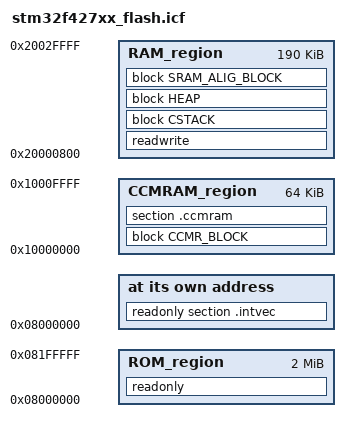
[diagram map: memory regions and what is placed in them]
/*###ICF### Section handled by ICF editor, don't touch! ****/
/*-Editor annotation file-*/
/* IcfEditorFile="$TOOLKIT_DIR$\config\ide\IcfEditor\cortex_v1_0.xml" */
/*-Specials-*/
define symbol __ICFEDIT_intvec_start__ = 0x08000000;
/*-Memory Regions-*/
define symbol __ICFEDIT_region_ROM_start__    = 0x08000000;
define symbol __ICFEDIT_region_ROM_end__      = 0x081FFFFF;
define symbol __ICFEDIT_region_RAM_start__    = 0x20000800;
define symbol __ICFEDIT_region_RAM_end__      = 0x2002FFFF;
define symbol __ICFEDIT_region_CCMRAM_start__ = 0x10000000;
define symbol __ICFEDIT_region_CCMRAM_end__   = 0x1000FFFF;
/*-Sizes-*/
define symbol __ICFEDIT_size_cstack__ = 0x1000;
define symbol __ICFEDIT_size_heap__ = 0x800;
/**** End of ICF editor section. ###ICF###*/


define memory mem with size = 4G;
define region ROM_region      = mem:[from __ICFEDIT_region_ROM_start__   to __ICFEDIT_region_ROM_end__];
define region RAM_region      = mem:[from __ICFEDIT_region_RAM_start__   to __ICFEDIT_region_RAM_end__];
define region CCMRAM_region   = mem:[from __ICFEDIT_region_CCMRAM_start__   to __ICFEDIT_region_CCMRAM_end__];

define block CSTACK    with alignment = 8, size = __ICFEDIT_size_cstack__   { };
define block HEAP      with alignment = 8, size = __ICFEDIT_size_heap__     { };

initialize by copy { readwrite };
do not initialize  { section .noinit };

place at address mem:__ICFEDIT_intvec_start__ { readonly section .intvec };

place in ROM_region   { readonly };
place in RAM_region   { readwrite,
                        block CSTACK, block HEAP };

/*自定义 SRAM存段，边界对齐方式：4字节对*/
define block SRAM_ALIG_BLOCK with alignment = 4 { section .sram_alig };
place in RAM_region { block SRAM_ALIG_BLOCK};

/*自定义 SDRAM内存段，边界对齐方式：缺省*/
/*place in SDRAM_region { section .sdram}; */

/*自定义 CCMR内存段，边界对齐方式：4字节对*/
define block CCMR_BLOCK with alignment = 4 { section .ccmram_alig };
place in CCMRAM_region { block CCMR_BLOCK};

/*自定义 CCMR内存段，边界对齐方式：缺省*/
place in CCMRAM_region { section .ccmram}; 
